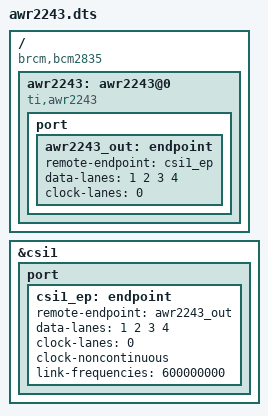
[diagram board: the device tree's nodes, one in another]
/dts-v1/;
/plugin/;

/ {
    compatible = "brcm,bcm2835";

    fragment@0 {
        target = <&csi1>;

        __overlay__ {
            status = "okay";

            port {
                csi1_ep: endpoint {
                    remote-endpoint = <&awr2243_out>;
                    data-lanes = <1 2 3 4>;
                    clock-lanes = <0>;
                    clock-noncontinuous;
                    link-frequencies = /bits/ 64 <600000000>; // 600 MHz
                };
            };
        };
    };

    fragment@1 {
        target-path = "/";

        __overlay__ {
            awr2243: awr2243@0 {
                compatible = "ti,awr2243";
                status = "okay";

                port {
                    awr2243_out: endpoint {
                        remote-endpoint = <&csi1_ep>;
                        data-lanes = <1 2 3 4>;
                        clock-lanes = <0>;
                    };
                };
            };
        };
    };
};
